# AVR64EA48 register map
Vendor: Atmel; File version: 1.0
CPU: other r0p0, little endian, no MPU, no FPU, 4 interrupt priority bits
Registers are 8-bit, read-write, reset 0x0 unless marked. A register's access mark holds for its fields unless they carry their own. Offsets are from the block's base; [hi:lo] are bit positions; {n}, {i} and the like mark numbered series; 'fields as' and 'values as' point back to an identical list.

## DAC0 — Digital to Analog Converter
Base 0x008006A0
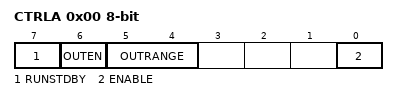
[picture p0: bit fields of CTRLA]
0x00 CTRLA — Control Register A
  [7] RUNSTDBY — Run in Standby Mode
  [6] OUTEN — Output Buffer Enable
  [5:4] OUTRANGE — Output Buffer Range
    0=AUTO (Output buffer automatically choose best range); 2=LOW (Output buffer configured to low range); 3=HIGH (Output buffer configured to high range)
  [0] ENABLE — DAC Enable
0x02 DATA 16-bit (reset mask 0xFF)
  [15:6] DATA

## EVSYS — Event System
Base 0x00800200
0x00 SWEVENTA — Software Event A
  [7:0] SWEVENTA wo — Software event on channel select
    1=CH0 (Software event on channel 0); 2=CH1 (Software event on channel 1); 4=CH2 (Software event on channel 2); 8=CH3 (Software event on channel 3); 16=CH4 (Software event on channel 4); 32=CH5 (Software event on channel 5); 64=CH6 (Software event on channel 6); 128=CH7 (Software event on channel 7)
{0x10+i} CHANNEL{i} (i=0..5) — Multiplexer Channel {i}
  [7:0] CHANNEL — Channel generator select
    0=OFF; 1=UPDI_SYNCH (UPDI SYNCH character); 6=RTC_OVF (Real Time Counter overflow); 7=RTC_CMP (Real Time Counter compare); 8=RTC_PITEV0 (Periodic Interrupt Timer Event 0); 9=RTC_PITEV1 (Periodic Interrupt Timer Event 1); {v}=CCL_LUT{v-16} (Configurable Custom Logic LUT{v-16}) (v=16..19); 32=AC0_OUT (Analog Comparator 0 out); 33=AC1_OUT (Analog Comparator 1 out); 36=ADC0_RES (ADC 0 Result Ready); 37=ADC0_SAMP (ADC 0 Sample Ready); 38=ADC0_WCMP (ADC 0 Window Compare); 64=PORTA_EV0 (Port A Event 0); 65=PORTA_EV1 (Port A Event 1); 66=PORTB_EV0 (Port B Event 0); 67=PORTB_EV1 (Port B Event 1); 68=PORTC_EV0 (Port C Event 0); 69=PORTC_EV1 (Port C Event 1); 70=PORTD_EV0 (Port D Event 0); 71=PORTD_EV1 (Port D Event 1); 72=PORTE_EV0 (Port E Event 0); 73=PORTE_EV1 (Port E Event 1); 74=PORTF_EV0 (Port F Event 0); 75=PORTF_EV1 (Port F Event 1); 96=USART0_XCK; 97=USART1_XCK; 98=USART2_XCK; 104=SPI0_SCK; 128=TCA0_OVF_LUNF (Timer/Counter A0 overflow / low byte timer underflow); 129=TCA0_HUNF (Timer/Counter A0 high byte timer underflow); 132=TCA0_CMP0_LCMP0 (Timer/Counter A0 compare 0 / low byte timer compare 0); 133=TCA0_CMP1_LCMP1 (Timer/Counter A0 compare 1 / low byte timer compare 1); 134=TCA0_CMP2_LCMP2 (Timer/Counter A0 compare 2 / low byte timer compare 2); 136=TCA1_OVF_LUNF (Timer/Counter A1 overflow / low byte timer underflow); 137=TCA1_HUNF (Timer/Counter A1 high byte timer underflow); 140=TCA1_CMP0_LCMP0 (Timer/Counter A1 compare 0 / low byte timer compare 0); 141=TCA1_CMP1_LCMP1 (Timer/Counter A1 compare 1 / low byte timer compare 1); 142=TCA1_CMP2_LCMP2 (Timer/Counter A1 compare 2 / low byte timer compare 2); 160=TCB0_CAPT (Timer/Counter B0 capture); 161=TCB0_OVF (Timer/Counter B0 overflow); 162=TCB1_CAPT (Timer/Counter B1 capture); 163=TCB1_OVF (Timer/Counter B1 overflow); 164=TCB2_CAPT (Timer/Counter B2 capture); 165=TCB2_OVF (Timer/Counter B2 overflow); 166=TCB3_CAPT (Timer/Counter B3 capture); 167=TCB3_OVF (Timer/Counter B3 overflow)
{0x20+2i} USERCCLLUT{i}A (i=0..3) — CCL{i} Event A
  [7:0] USER — User channel select
    0=OFF (Off, No Eventsys Channel connected); {v}=CHANNEL{v-1} (Connect user to event channel {v-1}) (v=1..6)
{0x21+2i} USERCCLLUT{i}B (i=0..3) — CCL{i} Event B
  fields as USERCCLLUT0A
0x28 USERADC0START — ADC0
  fields as USERCCLLUT0A
0x29 USEREVSYSEVOUTA — EVOUTA
  fields as USERCCLLUT0A
0x2A USEREVSYSEVOUTB — EVOUTB
  fields as USERCCLLUT0A
0x2B USEREVSYSEVOUTC — EVOUTC
  fields as USERCCLLUT0A
0x2C USEREVSYSEVOUTD — EVOUTD
  fields as USERCCLLUT0A
0x2D USEREVSYSEVOUTE — EVOUTE
  fields as USERCCLLUT0A
0x2E USEREVSYSEVOUTF — EVOUTF
  fields as USERCCLLUT0A
{0x2F+i} USERUSART{i}IRDA (i=0..2) — USART{i}
  fields as USERCCLLUT0A
0x32 USERTCA0CNTA — TCA0 Event A
  fields as USERCCLLUT0A
0x33 USERTCA0CNTB — TCA0 Event B
  fields as USERCCLLUT0A
0x34 USERTCA1CNTA — TCA1 Event A
  fields as USERCCLLUT0A
0x35 USERTCA1CNTB — TCA1 Event B
  fields as USERCCLLUT0A
{0x36+2i} USERTCB{i}CAPT (i=0..3) — TCB{i} Event A
  fields as USERCCLLUT0A
{0x37+2i} USERTCB{i}COUNT (i=0..3) — TCB{i} Event B
  fields as USERCCLLUT0A
